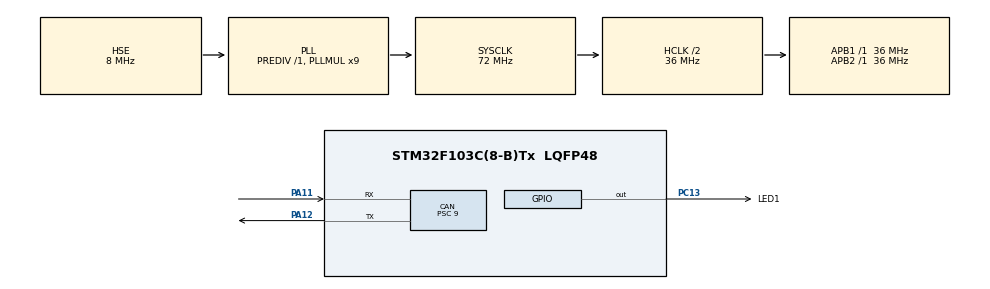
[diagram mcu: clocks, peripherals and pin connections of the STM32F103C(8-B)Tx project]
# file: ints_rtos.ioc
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CAN.BS1=CAN_BS1_13TQ
CAN.BS2=CAN_BS2_2TQ
CAN.CalculateTimeBit=4000
CAN.CalculateTimeQuantum=250.0
CAN.Prescaler=9
FREERTOS.Tasks01=defaultTask,0,128,StartDefaultTask,Default,NULL
Mcu.Family=STM32F1
Mcu.Name=STM32F103C(8-B)Tx
Mcu.Package=LQFP48
NVIC.CAN1_RX1_IRQn=true\:5\:0\:false\:false\:true\:true\:true
NVIC.CAN1_SCE_IRQn=true\:5\:0\:false\:false\:true\:true\:true
NVIC.PriorityGroup=NVIC_PRIORITYGROUP_4
NVIC.RCC_IRQn=true\:5\:0\:false\:false\:true\:true\:true
NVIC.TIM1_UP_IRQn=true\:0\:0\:false\:false\:true\:false\:false
NVIC.TimeBase=TIM1_UP_IRQn
NVIC.TimeBaseIP=TIM1
NVIC.USB_HP_CAN1_TX_IRQn=true\:5\:0\:false\:false\:true\:true\:true
NVIC.USB_LP_CAN1_RX0_IRQn=true\:5\:0\:false\:false\:true\:true\:true
PA11.Mode=Master
PA11.Signal=CAN_RX
PA12.Mode=Master
PA12.Signal=CAN_TX
PA13.Mode=Serial_Wire
PA13.Signal=SYS_JTMS-SWDIO
PA14.Mode=Serial_Wire
PA14.Signal=SYS_JTCK-SWCLK
PC13-TAMPER-RTC.GPIO_Label=LED1
PC13-TAMPER-RTC.Signal=GPIO_Output
PD0-OSC_IN.Mode=HSE-External-Oscillator
PD0-OSC_IN.Signal=RCC_OSC_IN
PD1-OSC_OUT.Mode=HSE-External-Oscillator
PD1-OSC_OUT.Signal=RCC_OSC_OUT
ProjectManager.HeapSize=0x200
ProjectManager.StackSize=0x400
ProjectManager.TargetToolchain=TrueSTUDIO
RCC.AHBCLKDivider=RCC_SYSCLK_DIV2
RCC.AHBFreq_Value=36000000
RCC.APB1Freq_Value=36000000
RCC.APB1TimFreq_Value=36000000
RCC.APB2Freq_Value=36000000
RCC.APB2TimFreq_Value=36000000
RCC.HCLKFreq_Value=36000000
RCC.PLLMUL=RCC_PLL_MUL9
RCC.PLLSourceVirtual=RCC_PLLSOURCE_HSE
RCC.SYSCLKFreq_VALUE=72000000
RCC.SYSCLKSource=RCC_SYSCLKSOURCE_PLLCLK
RCC.USBFreq_Value=72000000
VP_FREERTOS_VS_ENABLE.Mode=Enabled
VP_SYS_VS_tim1.Mode=TIM1
board=ints_rtos

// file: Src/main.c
/**
  ******************************************************************************
  * @file           : main.c
  * @brief          : Main program body
  ******************************************************************************
  * This notice applies to any and all portions of this file
  * that are not between comment pairs USER CODE BEGIN and
  * USER CODE END. Other portions of this file, whether
  * inserted by the user or by software development tools
  * are owned by their respective copyright owners.
  *
  * Copyright (c) 2018 STMicroelectronics International N.V.
  * All rights reserved.
  *
  * Redistribution and use in source and binary forms, with or without
  * modification, are permitted, provided that the following conditions are met:
  *
  * 1. Redistribution of source code must retain the above copyright notice,
  *    this list of conditions and the following disclaimer.
  * 2. Redistributions in binary form must reproduce the above copyright notice,
  *    this list of conditions and the following disclaimer in the documentation
  *    and/or other materials provided with the distribution.
  * 3. Neither the name of STMicroelectronics nor the names of other
  *    contributors to this software may be used to endorse or promote products
  *    derived from this software without specific written permission.
  * 4. This software, including modifications and/or derivative works of this
  *    software, must execute solely and exclusively on microcontroller or
  *    microprocessor devices manufactured by or for STMicroelectronics.
  * 5. Redistribution and use of this software other than as permitted under
  *    this license is void and will automatically terminate your rights under
  *    this license.
  *
  * THIS SOFTWARE IS PROVIDED BY STMICROELECTRONICS AND CONTRIBUTORS "AS IS"
  * AND ANY EXPRESS, IMPLIED OR STATUTORY WARRANTIES, INCLUDING, BUT NOT
  * LIMITED TO, THE IMPLIED WARRANTIES OF MERCHANTABILITY, FITNESS FOR A
  * PARTICULAR PURPOSE AND NON-INFRINGEMENT OF THIRD PARTY INTELLECTUAL PROPERTY
  * RIGHTS ARE DISCLAIMED TO THE FULLEST EXTENT PERMITTED BY LAW. IN NO EVENT
  * SHALL STMICROELECTRONICS OR CONTRIBUTORS BE LIABLE FOR ANY DIRECT, INDIRECT,
  * INCIDENTAL, SPECIAL, EXEMPLARY, OR CONSEQUENTIAL DAMAGES (INCLUDING, BUT NOT
  * LIMITED TO, PROCUREMENT OF SUBSTITUTE GOODS OR SERVICES; LOSS OF USE, DATA,
  * OR PROFITS; OR BUSINESS INTERRUPTION) HOWEVER CAUSED AND ON ANY THEORY OF
  * LIABILITY, WHETHER IN CONTRACT, STRICT LIABILITY, OR TORT (INCLUDING
  * NEGLIGENCE OR OTHERWISE) ARISING IN ANY WAY OUT OF THE USE OF THIS SOFTWARE,
  * EVEN IF ADVISED OF THE POSSIBILITY OF SUCH DAMAGE.
  *
  ******************************************************************************
  */
#include "main.h"
#include "stm32f1xx_hal.h"
#include "cmsis_os.h"

/* USER CODE BEGIN Includes */
#include <string.h>
/* USER CODE END Includes */

CAN_HandleTypeDef hcan;

osThreadId defaultTaskHandle;

/* USER CODE BEGIN PV */
/* Private variables ---------------------------------------------------------*/

/* USER CODE END PV */

void SystemClock_Config(void);
static void MX_GPIO_Init(void);
static void MX_CAN_Init(void);
void StartDefaultTask(void const * argument);

/* USER CODE BEGIN PFP */
/* Private function prototypes -----------------------------------------------*/

/* USER CODE END PFP */

/* USER CODE BEGIN 0 */
static void CanConfigFilter(void)
{
	CAN_FilterConfTypeDef  sFilterConfig;
	sFilterConfig.FilterNumber = 0;
	sFilterConfig.FilterMode = CAN_FILTERMODE_IDMASK;
	sFilterConfig.FilterScale = CAN_FILTERSCALE_32BIT;
	sFilterConfig.FilterIdHigh = 0x0000;
	sFilterConfig.FilterIdLow = 0x0000;
	sFilterConfig.FilterMaskIdHigh = 0x0000;
	sFilterConfig.FilterMaskIdLow = 0x0000;
	sFilterConfig.FilterFIFOAssignment = 0;
	sFilterConfig.FilterActivation = ENABLE;
	sFilterConfig.BankNumber = 14;
	if (HAL_CAN_ConfigFilter(&hcan, &sFilterConfig) != HAL_OK) {
		/* Filter configuration Error */
		//MyError_Handler();
	}
}
CanRxMsgTypeDef rxMsg;
CanTxMsgTypeDef txMsg;
int provisioned = 0;
uint32_t my_serial;
uint16_t my_id;
#define CAN_CARD_GENERIC			0x1B
#define CAN_CMD_CARDALIVE			0x04
#define CAN_CMD_CARD_PROVISION_REQ	0x07
#define CAN_CMD_CARD_PROVISION_RESP	0x08

void HAL_CAN_RxCpltCallback(CAN_HandleTypeDef* hcan)
{
	if (hcan->pRxMsg->Data[1] == CAN_CMD_CARD_PROVISION_RESP) {
		uint32_t recv_serial;
		memcpy(&recv_serial, &hcan->pRxMsg->Data[2], sizeof(recv_serial));
		if (recv_serial == my_serial) {
			provisioned = 1;
			memcpy(&my_id, &hcan->pRxMsg->Data[6], sizeof(my_id));
		}
	}
	HAL_GPIO_TogglePin(LED1_GPIO_Port, LED1_Pin);
	__HAL_CAN_ENABLE_IT(hcan, CAN_IT_FMP0);
}

/* USER CODE END 0 */

int main(void)
{

  /* MCU Configuration----------------------------------------------------------*/

  /* Reset of all peripherals, Initializes the Flash interface and the Systick. */
  HAL_Init();

  /* Configure the system clock */
  SystemClock_Config();

  /* Initialize all configured peripherals */
  MX_GPIO_Init();
  MX_CAN_Init();
  /* USER CODE BEGIN 2 */
  __HAL_RCC_CAN1_CLK_ENABLE();
  CanConfigFilter();
  hcan.pRxMsg = &rxMsg;
  hcan.pTxMsg = &txMsg;
  //HAL_CAN_Receive_IT(&hcan, CAN_FIFO0);
  /* USER CODE END 2 */

  /* Create the thread(s) */
  /* definition and creation of defaultTask */
  osThreadDef(defaultTask, StartDefaultTask, osPriorityNormal, 0, 128);
  defaultTaskHandle = osThreadCreate(osThread(defaultTask), NULL);

  /* Start scheduler */
  osKernelStart();

  /* We should never get here as control is now taken by the scheduler */

  /* Infinite loop */
  while (1)
  {

  }

}

void SystemClock_Config(void)
{

  RCC_OscInitTypeDef RCC_OscInitStruct;
  RCC_ClkInitTypeDef RCC_ClkInitStruct;

    /**Initializes the CPU, AHB and APB busses clocks
    */
  RCC_OscInitStruct.OscillatorType = RCC_OSCILLATORTYPE_HSE;
  RCC_OscInitStruct.HSEState = RCC_HSE_ON;
  RCC_OscInitStruct.HSEPredivValue = RCC_HSE_PREDIV_DIV1;
  RCC_OscInitStruct.HSIState = RCC_HSI_ON;
  RCC_OscInitStruct.PLL.PLLState = RCC_PLL_ON;
  RCC_OscInitStruct.PLL.PLLSource = RCC_PLLSOURCE_HSE;
  RCC_OscInitStruct.PLL.PLLMUL = RCC_PLL_MUL9;
  if (HAL_RCC_OscConfig(&RCC_OscInitStruct) != HAL_OK)
  {
    _Error_Handler(__FILE__, __LINE__);
  }

    /**Initializes the CPU, AHB and APB busses clocks
    */
  RCC_ClkInitStruct.ClockType = RCC_CLOCKTYPE_HCLK|RCC_CLOCKTYPE_SYSCLK
                              |RCC_CLOCKTYPE_PCLK1|RCC_CLOCKTYPE_PCLK2;
  RCC_ClkInitStruct.SYSCLKSource = RCC_SYSCLKSOURCE_PLLCLK;
  RCC_ClkInitStruct.AHBCLKDivider = RCC_SYSCLK_DIV2;
  RCC_ClkInitStruct.APB1CLKDivider = RCC_HCLK_DIV1;
  RCC_ClkInitStruct.APB2CLKDivider = RCC_HCLK_DIV1;

  if (HAL_RCC_ClockConfig(&RCC_ClkInitStruct, FLASH_LATENCY_2) != HAL_OK)
  {
    _Error_Handler(__FILE__, __LINE__);
  }

    /**Configure the Systick interrupt time
    */
  HAL_SYSTICK_Config(HAL_RCC_GetHCLKFreq()/1000);

    /**Configure the Systick
    */
  HAL_SYSTICK_CLKSourceConfig(SYSTICK_CLKSOURCE_HCLK);

  /* SysTick_IRQn interrupt configuration */
  HAL_NVIC_SetPriority(SysTick_IRQn, 15, 0);
}

/* CAN init function */
static void MX_CAN_Init(void)
{

  hcan.Instance = CAN1;
  hcan.Init.Prescaler = 9;
  hcan.Init.Mode = CAN_MODE_NORMAL;
  hcan.Init.SJW = CAN_SJW_1TQ;
  hcan.Init.BS1 = CAN_BS1_13TQ;
  hcan.Init.BS2 = CAN_BS2_2TQ;
  hcan.Init.TTCM = DISABLE;
  hcan.Init.ABOM = DISABLE;
  hcan.Init.AWUM = DISABLE;
  hcan.Init.NART = DISABLE;
  hcan.Init.RFLM = DISABLE;
  hcan.Init.TXFP = DISABLE;
  if (HAL_CAN_Init(&hcan) != HAL_OK)
  {
    _Error_Handler(__FILE__, __LINE__);
  }

}

/** Configure pins as
        * Analog
        * Input
        * Output
        * EVENT_OUT
        * EXTI
*/
static void MX_GPIO_Init(void)
{

  GPIO_InitTypeDef GPIO_InitStruct;

  /* GPIO Ports Clock Enable */
  __HAL_RCC_GPIOC_CLK_ENABLE();
  __HAL_RCC_GPIOD_CLK_ENABLE();
  __HAL_RCC_GPIOA_CLK_ENABLE();

  /*Configure GPIO pin Output Level */
  HAL_GPIO_WritePin(LED1_GPIO_Port, LED1_Pin, GPIO_PIN_RESET);

  /*Configure GPIO pin : LED1_Pin */
  GPIO_InitStruct.Pin = LED1_Pin;
  GPIO_InitStruct.Mode = GPIO_MODE_OUTPUT_PP;
  GPIO_InitStruct.Speed = GPIO_SPEED_FREQ_LOW;
  HAL_GPIO_Init(LED1_GPIO_Port, &GPIO_InitStruct);

}

/* USER CODE BEGIN 4 */
static uint32_t
hash_djb2 (unsigned char *input, int len)
{
	uint32_t hash = 5381;
	int c;

	while (len--) {
		c = *input++;
		hash = ((hash << 5) + hash) + c; /* hash * 33 + c */
	}
	return hash;
}

static void send_provision_msg (void)
{
	unsigned char uid[14] = {0};

	HAL_GetUID((uint32_t*)uid);
	my_serial = hash_djb2(uid, 12);

	txMsg.DLC = 7;
	txMsg.IDE = CAN_ID_STD;
	txMsg.RTR = CAN_RTR_DATA;
	txMsg.StdId = 1;
	txMsg.Data[0] = CAN_CARD_GENERIC;
	txMsg.Data[1] = CAN_CMD_CARD_PROVISION_REQ;
	txMsg.Data[2] = CAN_CARD_GENERIC;
	txMsg.Data[3] = my_serial & 0xFF;			// 8 LSB, card id
	txMsg.Data[4] = (my_serial >> 8) & 0xFF;		// 3 MSB, card id
	txMsg.Data[5] = (my_serial >> 16) & 0xFF;		// 3 MSB, card id
	txMsg.Data[6] = (my_serial >> 24) & 0xFF;		// 3 MSB, card id
	HAL_CAN_Transmit(&hcan, 100);
}

static void send_ka (void)
{
	txMsg.IDE = CAN_ID_STD;
	txMsg.RTR = CAN_RTR_DATA;
	txMsg.StdId = 1;
	txMsg.DLC = 5;
	txMsg.Data[0] = my_id;
	txMsg.Data[1] = CAN_CMD_CARDALIVE;
	txMsg.Data[2] = CAN_CARD_GENERIC;
	txMsg.Data[3] = 0x02; // major ver
	txMsg.Data[4] = 0x03; // minor ver
	HAL_CAN_Transmit(&hcan, 100);
}
/* USER CODE END 4 */

/* StartDefaultTask function */
void StartDefaultTask(void const * argument)
{

  /* USER CODE BEGIN 5 */
	HAL_CAN_Receive_IT(&hcan, CAN_FIFO0);
	while(1) {
		if (!provisioned) {
			send_provision_msg();
		} else {
			send_ka();
		}
		osDelay(1000);
	}

  /* USER CODE END 5 */
}

void HAL_TIM_PeriodElapsedCallback(TIM_HandleTypeDef *htim)
{
  if (htim->Instance == TIM1) {
    HAL_IncTick();
  }
}

void _Error_Handler(char *file, int line)
{
  while(1)
  {
  }
}

/************************ (C) COPYRIGHT STMicroelectronics *****END OF FILE****/
